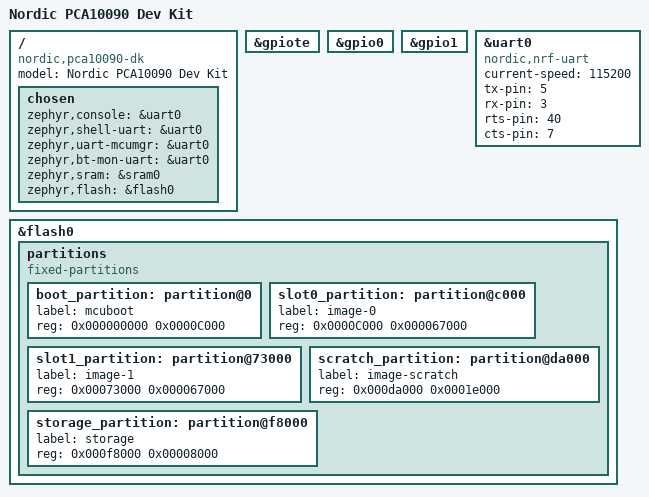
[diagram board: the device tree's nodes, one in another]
/*
 * Copyright (c) 2018 Nordic Semiconductor ASA
 * Copyright (c) 2017 Linaro Limited
 *
 * SPDX-License-Identifier: Apache-2.0
 */

/dts-v1/;
#include <nordic/nrf52840_qiaa.dtsi>

/ {
	model = "Nordic PCA10090 Dev Kit";
	compatible = "nordic,pca10090-dk", "nordic,nrf52840-qiaa",
		     "nordic,nrf52840";

	chosen {
		zephyr,console = &uart0;
		zephyr,shell-uart = &uart0;
		zephyr,uart-mcumgr = &uart0;
		zephyr,bt-mon-uart = &uart0;
		zephyr,sram = &sram0;
		zephyr,flash = &flash0;
	};
};

&gpiote {
	status = "okay";
};

&gpio0 {
	status = "okay";
};

&gpio1 {
	status = "okay";
};

/* The nRF52840 SoC does not have any connection to the any of the LEDs,
 * buttons, switches and Arduino pin headers on the PCA10090 board.
 */

&uart0 {
	compatible = "nordic,nrf-uart";
	current-speed = <115200>;
	status = "okay";
	tx-pin = <5>;
	rx-pin = <3>;
	rts-pin = <40>;
	cts-pin = <7>;
};

&flash0 {
	/*
	 * For more information, see:
	 * http://docs.zephyrproject.org/latest/guides/dts/index.html#flash-partitions
	 */
	partitions {
		compatible = "fixed-partitions";
		#address-cells = <1>;
		#size-cells = <1>;

		boot_partition: partition@0 {
			label = "mcuboot";
			reg = <0x000000000 0x0000C000>;
		};
		slot0_partition: partition@c000 {
			label = "image-0";
			reg = <0x0000C000 0x000067000>;
		};
		slot1_partition: partition@73000 {
			label = "image-1";
			reg = <0x00073000 0x000067000>;
		};
		scratch_partition: partition@da000 {
			label = "image-scratch";
			reg = <0x000da000 0x0001e000>;
		};

		/*
		 * The flash starting at 0x000f8000 and ending at
		 * 0x000fffff is reserved for use by the application.
		 */

		/* Storage partition will be used by FCB/NFFS/NVS if enabled. */
		storage_partition: partition@f8000 {
			label = "storage";
			reg = <0x000f8000 0x00008000>;
		};
	};
};
